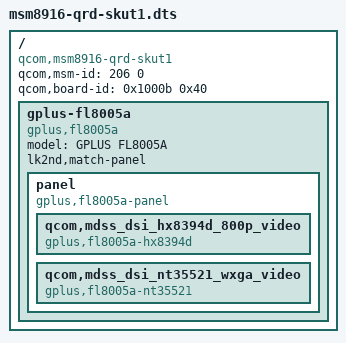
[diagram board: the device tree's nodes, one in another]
// SPDX-License-Identifier: GPL-2.0-only

/dts-v1/;

#include <skeleton.dtsi>

/ {
	compatible = "qcom,msm8916-qrd-skut1", "qcom,msm8916";
	qcom,msm-id = <206 0>;
	qcom,board-id = <0x1000b 0x40>;

	gplus-fl8005a {
		model = "GPLUS FL8005A";
		compatible = "gplus,fl8005a", "qcom,msm8916", "lk2nd,device";
		lk2nd,match-panel;

		panel {
			compatible = "gplus,fl8005a-panel";

			qcom,mdss_dsi_hx8394d_800p_video {
				compatible = "gplus,fl8005a-hx8394d";
			};

			qcom,mdss_dsi_nt35521_wxga_video {
				compatible = "gplus,fl8005a-nt35521";
			};
		};
	};
};
